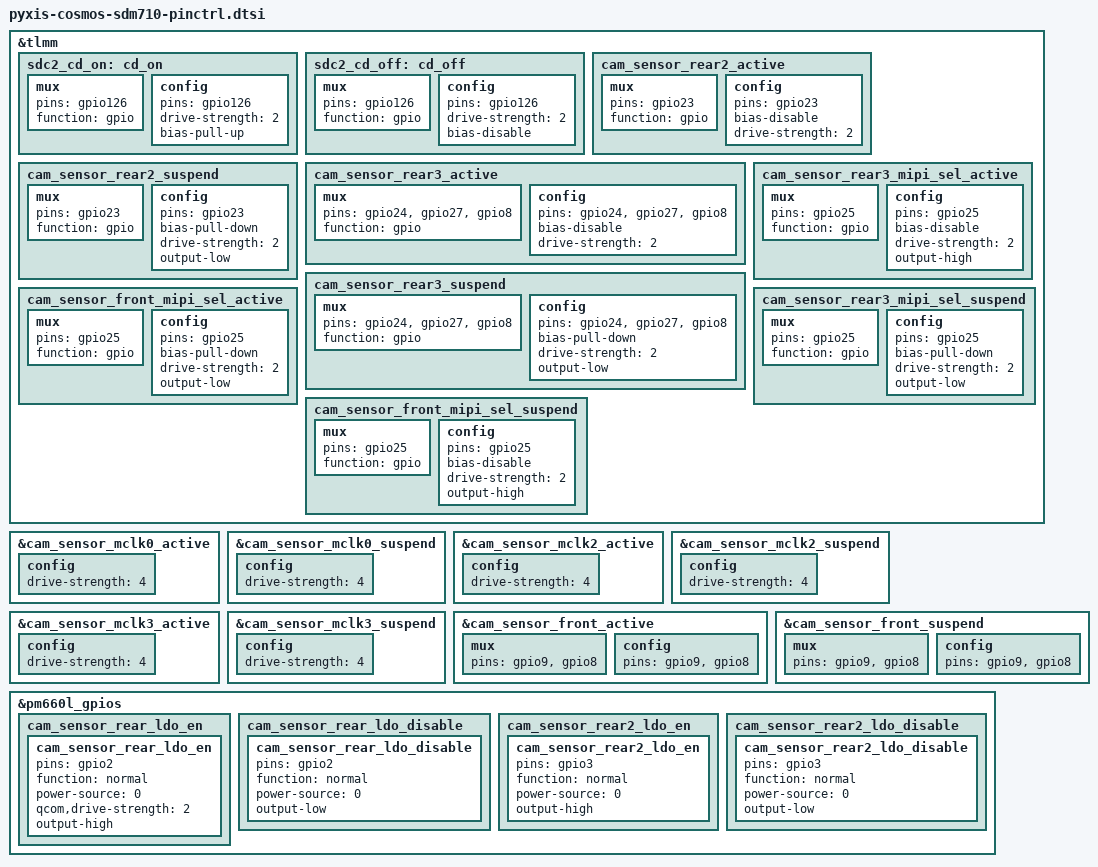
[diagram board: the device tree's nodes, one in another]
/* gpio resource override for pyxis(sdm710) */

&tlmm {
	sdc2_cd_on: cd_on {
		mux {
			pins = "gpio126";
			function = "gpio";
		};

		config {
			pins = "gpio126";
			drive-strength = <2>;
			bias-pull-up;
		};
	};

	sdc2_cd_off: cd_off {
		mux {
			pins = "gpio126";
			function = "gpio";
		};

		config {
			pins = "gpio126";
			drive-strength = <2>;
			bias-disable;
		};
	};

	cam_sensor_rear2_active: cam_sensor_rear2_active {
		/* RESET */
		mux {
			pins = "gpio23";
			function = "gpio";
		};

		config {
			pins = "gpio23";
			bias-disable; /* No PULL */
			drive-strength = <2>; /* 2 MA */
		};
	};

	cam_sensor_rear2_suspend: cam_sensor_rear2_suspend {
		/* RESET */
		mux {
			pins = "gpio23";
			function = "gpio";
		};

		config {
			pins = "gpio23";
			bias-pull-down; /* PULL DOWN */
			drive-strength = <2>; /* 2 MA */
			output-low;
		};
	};

	cam_sensor_rear3_active: cam_sensor_rear3_active {
		/* RESET, DVDD ENABLE, AVDD ENABLE */
		mux {
			pins = "gpio24", "gpio27", "gpio8";
			function = "gpio";
		};

		config {
			pins = "gpio24", "gpio27", "gpio8";
			bias-disable; /* No PULL */
			drive-strength = <2>; /* 2 MA */
		};
	};

	cam_sensor_rear3_suspend: cam_sensor_rear3_suspend {
		/* RESET, DVDD DISABLE, AVDD DISABLE */
		mux {
			pins = "gpio24", "gpio27", "gpio8";
			function = "gpio";
		};

		config {
			pins = "gpio24", "gpio27", "gpio8";
			bias-pull-down; /* PULL DOWN */
			drive-strength = <2>; /* 2 MA */
			output-low;
		};
	};

	cam_sensor_rear3_mipi_sel_active: cam_sensor_rear3_mipi_sel_active {
		/* MIPI SEL */
		mux {
			pins = "gpio25";
			function = "gpio";
		};

		config {
			pins = "gpio25";
			bias-disable; /* No PULL */
			drive-strength = <2>; /* 2 MA */
			output-high;
		};
	};

	cam_sensor_rear3_mipi_sel_suspend: cam_sensor_rear3_mipi_sel_suspend {
		/* MIPI SEL */
		mux {
			pins = "gpio25";
			function = "gpio";
		};

		config {
			pins = "gpio25";
			bias-pull-down; /* PULL DOWN */
			drive-strength = <2>; /* 2 MA */
			output-low;
		};
	};

	cam_sensor_front_mipi_sel_active: cam_sensor_front_mipi_sel_active {
		/* MIPI SEL */
		mux {
			pins = "gpio25";
			function = "gpio";
		};

		config {
			pins = "gpio25";
			bias-pull-down; /* PULL DOWN */
			drive-strength = <2>; /* 2 MA */
			output-low;
		};
	};

	cam_sensor_front_mipi_sel_suspend: cam_sensor_front_mipi_sel_suspend {
		/* MIPI SEL */
		mux {
			pins = "gpio25";
			function = "gpio";
		};

		config {
			pins = "gpio25";
			bias-disable; /* No PULL */
			drive-strength = <2>; /* 2 MA */
			output-high;
		};
	};
};

&cam_sensor_mclk0_active {
	config {
		drive-strength = <4>; /* 4 MA */
	};
};

&cam_sensor_mclk0_suspend {
	config {
		drive-strength = <4>; /* 4 MA */
	};
};

&cam_sensor_mclk2_active {
	config {
		drive-strength = <4>; /* 4 MA */
	};
};

&cam_sensor_mclk2_suspend {
	config {
		drive-strength = <4>; /* 4 MA */
	};
};

&cam_sensor_mclk3_active {
	config {
		drive-strength = <4>; /* 4 MA */
	};
};

&cam_sensor_mclk3_suspend {
	config {
		drive-strength = <4>; /* 4 MA */
	};
};

&cam_sensor_front_active {
	/* RESET, AVDD/DVDD ENABLE */
	mux {
		pins = "gpio9", "gpio8";
	};

	config {
		pins = "gpio9", "gpio8";
	};
};

&cam_sensor_front_suspend {
	/* RESET, AVDD/DVDD DISABLE */
	mux {
		pins = "gpio9", "gpio8";
	};

	config {
		pins = "gpio9", "gpio8";
	};
};

&pm660l_gpios {
	cam_sensor_rear_ldo_en {
		cam_sensor_rear_ldo_en: cam_sensor_rear_ldo_en {
			pins = "gpio2";
			function = "normal";
			power-source = <0>;
			qcom,drive-strength = <2>;
			output-high;
		};
	};

	cam_sensor_rear_ldo_disable {
		cam_sensor_rear_ldo_disable: cam_sensor_rear_ldo_disable {
			pins = "gpio2";
			function = "normal";
			power-source = <0>;
			output-low;
		};
	};

	cam_sensor_rear2_ldo_en {
		cam_sensor_rear2_ldo_en: cam_sensor_rear2_ldo_en {
			pins = "gpio3";
			function = "normal";
			power-source = <0>;
			output-high;
		};
	};

	cam_sensor_rear2_ldo_disable {
		cam_sensor_rear2_ldo_disable: cam_sensor_rear2_ldo_disable {
			pins = "gpio3";
			function = "normal";
			power-source = <0>;
			output-low;
		};
	};
};
